# MCXN947_cm33_core0 register map
Vendor: nxp.com; File version: 1.0
CPU: CM33 r2p0, little endian, MPU, FPU, VTOR, 3 interrupt priority bits
Registers are 32-bit, read-write, reset 0x0 unless marked. A register's access mark holds for its fields unless they carry their own. Offsets are from the block's base; [hi:lo] are bit positions; {n}, {i} and the like mark numbered series.

## ELS
Base 0x40054000
Same registers: ELS_ALIAS1 0x40055000, ELS_ALIAS2 0x40056000, ELS_ALIAS3 0x40057000
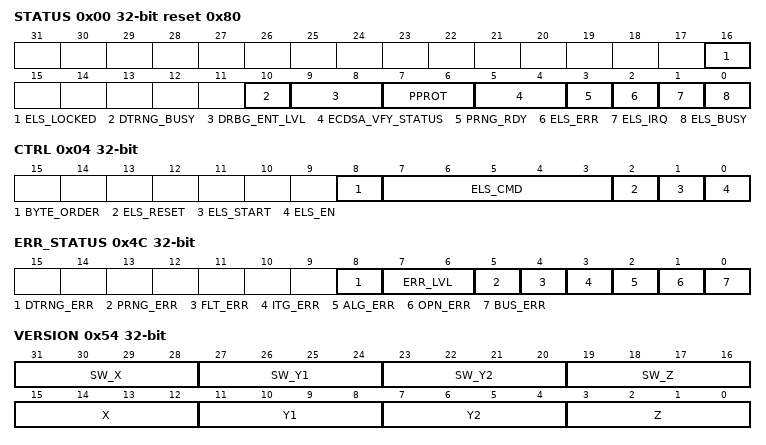
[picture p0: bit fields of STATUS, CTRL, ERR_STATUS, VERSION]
0x00 STATUS ro reset 0x80
  [16] ELS_LOCKED — When set, indicates that ELS is locked by a master
    0=Not locked by master; 1=Locked by master
  [10] DTRNG_BUSY — When set, it indicates TRNG is gathering entropy
    0=notent (Not gathering entropy); 1=ent (Gathering entropy)
  [9:8] DRBG_ENT_LVL — Entropy quality of the current DRBG instance
    0=none; 1=low (LOW, DRBG generates random numbers of low quality entropy); 2=HIGH, DRBG generates random numbers of high quality entropy
  [7:6] PPROT — Current command privilege level
    0=secnp (Secure, non-privileged); 1=secp (Secure, privileged); 2=nsecnp (Non-secure, non-privileged); 3=nsecp (Non-secure, privileged)
  [5:4] ECDSA_VFY_STATUS — Signature verify result status
    0=no_v_run (No verify run); 1=sig_fail (Signature verify failed); 2=sig_pass (Signature verify passed); 3=err (Invalid, Error)
  [3] PRNG_RDY — When set, indicates the internal PRNG is ready
    0=ntready (Internal PRNG not ready); 1=ready (Internal PRNG ready)
  [2] ELS_ERR — When set, indicates the ELS has detected an internal error
    0=nterr (Internal error not detected); 1=err (Internal error detected)
  [1] ELS_IRQ — When set, indicates the ELS has an active interrupt
    0=ntint (No active interrupt); 1=int (Active interrupt)
  [0] ELS_BUSY — When set, indicates the ELS is executing a crypto sequence
    0=ntcry (Crypto sequence not executing); 1=Crypto sequence executing
0x04 CTRL — Control Register
  [8] BYTE_ORDER — Defines endianness
    0=lit (Little endian); 1=big (Big endian)
  [7:3] ELS_CMD — ELS Command ID
  [2] ELS_RESET — Write to 1 to perform a ELS synchronous reset. Writing 0 has no effect.
  [1] ELS_START — Write to 1 to start an ELS operation. Writing 0 has no effect.
  [0] ELS_EN — ELS enable
    0=dis (Disabled); 1=en (Enabled)
0x08 CMDCFG0 — Command Configuration Register
  [31:0] CMDCFG0 — See
0x0C CFG — Configuration Register
  [25:16] ADCTRL — Maximum aes start delay
0x10 KIDX0 — Keystore Index 0 Register
  [4:0] KIDX0 — Keystore is indexed as an array of 128 bit key slots
0x14 KIDX1 — Keystore Index 1 Register
  [4:0] KIDX1 — Keystore is indexed as an array of 128 bit key slots
0x18 KPROPIN — Key Properties Request Register
  [31:0] KPROPIN — For commands that create a key - requested properties of the key that is being created
{0x20+8i} DMA_SRC{i} (i=0..2) — DMA Source {i} Register
  [31:0] ADDR_SRC{i} — Defines the system address of the start of the data to be transferred to the ELS via DMA
0x24 DMA_SRC0_LEN — DMA Source 0 Length Register
  [31:0] SIZE_SRC0_LEN — Size in bytes of the data to be transferred from the target defined in SFR DMA_SRC0
0x34 DMA_SRC2_LEN — DMA Source 2 Length Register
  [31:0] SIZE_SRC2_LEN — Size in bytes of the data to be transferred from the target defined in SFR DMA_SRC2
0x38 DMA_RES0 — DMA Result 0 Register
  [31:0] ADDR_RES0 — Defines the system start address where the result of the ELS operation is transferred via DMA
0x3C DMA_RES0_LEN — DMA Result 0 Size Register
  [31:0] SIZE_RES0_LEN — Size in bytes of the data to be transferred
0x40 INT_ENABLE — Interrupt Enable Register
  [0] INT_EN — Interrupt enable bit
0x44 INT_STATUS_CLR wo — Interrupt Status Clear Register
  [0] INT_CLR — Interrupt status clear
0x48 INT_STATUS_SET wo — Interrupt Status Set Register
  [0] INT_SET — Sets interrupt by software
0x4C ERR_STATUS ro — Error Status Register
  [8] DTRNG_ERR — TRNG unable to gather entropy with the current configuration
  [7:6] ERR_LVL — Indicates the triggered error level: 0, 1 ,2
  [5] PRNG_ERR — User read of PRNG_DATOUT when STATUS[PRNG_RDY] is 0
  [4] FLT_ERR — Indicates hardware fault error: attempt to change the value of an internal register
  [3] ITG_ERR — Indicates data integrity error: internal data integrity check failed
  [2] ALG_ERR — Indicates algorithm error: an internal algorithm has produced an unexpected result
  [1] OPN_ERR — Indicates operational error: ELS has been incorrectly operated
  [0] BUS_ERR — Indicates bus access error: public or private bus
0x50 ERR_STATUS_CLR wo — Error Status Clear Register
  [0] ERR_CLR
    0=Exits ELS error state; 1=clr (Clears ELS error status bits)
0x54 VERSION ro
  [31:28] SW_X — Software major release version: possible values are from 1-9
  [27:24] SW_Y1 — Software minor release version digit1: possible values are from 0-9
  [23:20] SW_Y2 — Software minor release version digit0: possible values are from 0-9
  [19:16] SW_Z — Software extended revision version: possible values are from 0-9
  [15:12] X — Major release version: possible values are from 1-9
  [11:8] Y1 — Minor release version digit1: possible values are from 0-9
  [7:4] Y2 — Minor release version digit0: possible values are from 0-9
  [3:0] Z — Extended release version digit1: possible values are from 0-9
0x5C PRNG_DATOUT ro reset not defined — PRNG SW Read Out Register
  [31:0] PRNG_DATOUT — 32-bit wide pseudo-random number
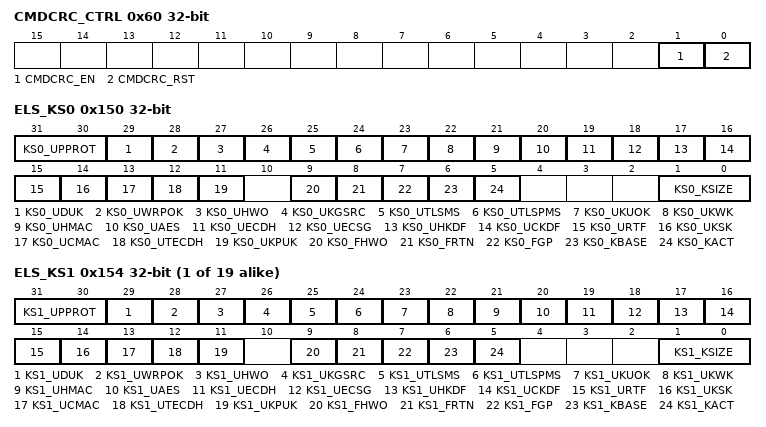
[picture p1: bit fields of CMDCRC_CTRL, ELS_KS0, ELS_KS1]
0x60 CMDCRC_CTRL — CRC Configuration Register
  [1] CMDCRC_EN — CRC enable bit
  [0] CMDCRC_RST — CRC reset to initial value
0x64 CMDCRC ro reset 0xA5A5A5A5 — Command CRC Value Register
  [31:0] CMDCRC — Current CRC value
0x68 SESSION_ID reset 0xCE2C6AF1
0x70 DMA_FIN_ADDR ro — Final DMA Address Register
  [31:0] DMA_FIN_ADDR — Final AHB address presented by ELS DMA to the system
0x74 MASTER_ID reset 0x1F
  [4:0] MASTER_ID — High Priviledge Master ID
0x78 KIDX2 — Keystore Index 2 Register
  [4:0] KIDX2 — Keystore is indexed as an array of 128 bit key slots
0x150 ELS_KS0 ro (reset mask 0x41C) — Status Register
  [31:30] KS0_UPPROT — Priviledge level
  [29] KS0_UDUK — Device Unique Key
  [28] KS0_UWRPOK — Wrap key
  [27] KS0_UHWO — Hardware out key
  [26] KS0_UKGSRC — Supply KEYGEN source
  [25] KS0_UTLSMS — TLS Master Secret
  [24] KS0_UTLSPMS — TLS Pre Master Secret
  [23] KS0_UKUOK — Key unwrapping key
  [22] KS0_UKWK — Key wrapping key
  [21] KS0_UHMAC — Hmac key
  [20] KS0_UAES — Aes key
  [19] KS0_UECDH — Ecc diffie hellman key
  [18] KS0_UECSG — Ecc signing key
  [17] KS0_UHKDF — Derivation key for HKDF command
  [16] KS0_UCKDF — Derivation key for CKDF command
  [15] KS0_URTF — Real Time Fingerprint key
  [14] KS0_UKSK — KSK key
  [13] KS0_UCMAC — CMAC key
  [12] KS0_UTECDH — CMAC key
  [11] KS0_UKPUK — CMAC key
  [9] KS0_FHWO — Hardware Feature Output
  [8] KS0_FRTN — Hardware Feature Retention
  [7] KS0_FGP — Hardware Feature General Purpose
  [6] KS0_KBASE — First slot in a multislot key
  [5] KS0_KACT — Key is active
  [1:0] KS0_KSIZE — Key size
    0=size128 (128); 1=size256 (256)
{0x150+4i} ELS_KS{i} ro (reset mask 0x41C) (i=1..19) — Status Register
  [31:30] KS{i}_UPPROT — Priviledge level
  [29] KS{i}_UDUK — Device Unique Key
  [28] KS{i}_UWRPOK — Ok to wrap key
  [27] KS{i}_UHWO — Hardware out key
  [26] KS{i}_UKGSRC — Supply KEYGEN source
  [25] KS{i}_UTLSMS — TLS Master Secret
  [24] KS{i}_UTLSPMS — TLS Pre Master Secret
  [23] KS{i}_UKUOK — Key unwrapping key
  [22] KS{i}_UKWK — Key wrapping key
  [21] KS{i}_UHMAC — Hmac key
  [20] KS{i}_UAES — Aes key
  [19] KS{i}_UECDH — Ecc diffie hellman key
  [18] KS{i}_UECSG — Ecc signing key
  [17] KS{i}_UHKDF — Derivation key for HKDF command
  [16] KS{i}_UCKDF — Derivation key for CKDF command
  [15] KS{i}_URTF — Real Time Fingerprint key
  [14] KS{i}_UKSK — KSK key
  [13] KS{i}_UCMAC — CMAC key
  [12] KS{i}_UTECDH — CMAC key
  [11] KS{i}_UKPUK — CMAC key
  [9] KS{i}_FHWO — Hardware Feature Output
  [8] KS{i}_FRTN — Hardware Feature Retention
  [7] KS{i}_FGP — Hardware Feature General Purpose
  [6] KS{i}_KBASE — First slot in a multislot key
  [5] KS{i}_KACT — Key is active
  [1:0] KS{i}_KSIZE — Key size
    0=size128 (128); 1=size256 (256)
